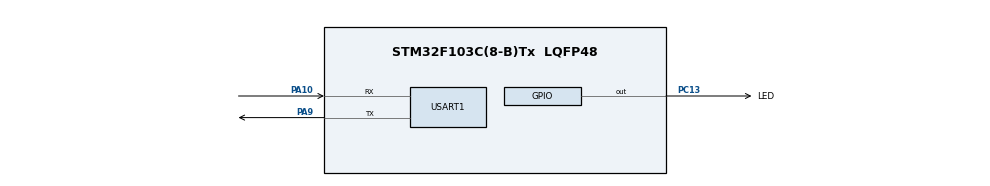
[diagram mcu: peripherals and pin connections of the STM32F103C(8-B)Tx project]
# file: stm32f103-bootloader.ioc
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Mcu.Family=STM32F1
Mcu.Name=STM32F103C(8-B)Tx
Mcu.Package=LQFP48
NVIC.PriorityGroup=NVIC_PRIORITYGROUP_4
NVIC.TIM4_IRQn=true\:0\:0\:false\:false\:true\:true\:true\:true
NVIC.USART1_IRQn=true\:0\:0\:false\:false\:true\:true\:true\:true
PA10.Mode=Asynchronous
PA10.Signal=USART1_RX
PA13.Mode=Serial_Wire
PA13.Signal=SYS_JTMS-SWDIO
PA14.Mode=Serial_Wire
PA14.Signal=SYS_JTCK-SWCLK
PA9.Mode=Asynchronous
PA9.Signal=USART1_TX
PC13-TAMPER-RTC.GPIO_Label=LED
PC13-TAMPER-RTC.Signal=GPIO_Output
PD0-OSC_IN.Mode=HSE-External-Oscillator
PD0-OSC_IN.Signal=RCC_OSC_IN
PD1-OSC_OUT.Mode=HSE-External-Oscillator
PD1-OSC_OUT.Signal=RCC_OSC_OUT
ProjectManager.HeapSize=0x200
ProjectManager.StackSize=0x400
ProjectManager.TargetToolchain=STM32CubeIDE
RCC.AHBFreq_Value=72000000
RCC.APB1CLKDivider=RCC_HCLK_DIV2
RCC.APB1Freq_Value=36000000
RCC.APB1TimFreq_Value=72000000
RCC.APB2Freq_Value=72000000
RCC.APB2TimFreq_Value=72000000
RCC.HCLKFreq_Value=72000000
RCC.PLLMUL=RCC_PLL_MUL9
RCC.PLLSourceVirtual=RCC_PLLSOURCE_HSE
RCC.SYSCLKFreq_VALUE=72000000
RCC.SYSCLKSource=RCC_SYSCLKSOURCE_PLLCLK
RCC.USBFreq_Value=72000000
TIM4.Period=71
TIM4.Prescaler=1749
TIM4.TIM_MasterOutputTrigger=TIM_TRGO_UPDATE
USART1.VirtualMode=VM_ASYNC
VP_TIM4_VS_ClockSourceINT.Mode=Internal
board=custom

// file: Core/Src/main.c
/* USER CODE BEGIN Header */
/**
 ******************************************************************************
 * @file           : main.c
 * @brief          : Main program body
 ******************************************************************************
 * @attention
 *
 * Copyright (c) 2023 STMicroelectronics.
 * All rights reserved.
 *
 * This software is licensed under terms that can be found in the LICENSE file
 * in the root directory of this software component.
 * If no LICENSE file comes with this software, it is provided AS-IS.
 *
 ******************************************************************************
 */
/* USER CODE END Header */
#include "main.h"

/* USER CODE BEGIN Includes */
#include "modbus_callbacks.h"
#include "bootloader.h"

#include <stddef.h>

#include "mb.h"
/* USER CODE END Includes */

/* USER CODE BEGIN PV */
int bootloader_started_programming;
int bootloader_needs_reset;
/* USER CODE END PV */

void SystemClock_Config(void);
static void MX_GPIO_Init(void);
static void MX_USART1_UART_Init(void);
static void MX_TIM4_Init(void);

int main(void)
{

  /* MCU Configuration--------------------------------------------------------*/

  /* Reset of all peripherals, Initializes the Flash interface and the Systick. */
  LL_APB2_GRP1_EnableClock(LL_APB2_GRP1_PERIPH_AFIO);
  LL_APB1_GRP1_EnableClock(LL_APB1_GRP1_PERIPH_PWR);

  /* System interrupt init*/
  NVIC_SetPriorityGrouping(NVIC_PRIORITYGROUP_4);

  /* SysTick_IRQn interrupt configuration */
  NVIC_SetPriority(SysTick_IRQn,
      NVIC_EncodePriority(NVIC_GetPriorityGrouping(), 15, 0));

  /** NOJTAG: JTAG-DP Disabled and SW-DP Enabled
   */
  LL_GPIO_AF_Remap_SWJ_NOJTAG();

  /* Configure the system clock */
  SystemClock_Config();

  /* Initialize all configured peripherals */
  MX_GPIO_Init();
  MX_USART1_UART_Init();
  MX_TIM4_Init();
  /* USER CODE BEGIN 2 */
  eMBInit(MB_RTU, 1, 0, 115200, MB_PAR_NONE);
  eMBEnable();
  eMBRegisterCB(MB_FLASH_UPDATE_FUNCION_CODE, eMBFlashUpdateCB);
  /* USER CODE END 2 */

  /* Infinite loop */
  /* USER CODE BEGIN WHILE */

  for (int i = 0; i < 50; ++i) {
    eMBPoll();
    if (bootloader_started_programming) {
      bootloader_started_programming = 0;
      LL_GPIO_SetOutputPin(LED_GPIO_Port, LED_Pin);
      while (1) {
        eMBPoll();
        if (bootloader_needs_reset) {
          LL_mDelay(100);
          bootloader_needs_reset = 0;
          bootloader_reset_device();
        }
      }
    }

    LL_mDelay(100);
    LL_GPIO_TogglePin(LED_GPIO_Port, LED_Pin);
    /* USER CODE END WHILE */

    /* USER CODE BEGIN 3 */
  }

  LL_GPIO_ResetOutputPin(LED_GPIO_Port, LED_Pin);

  eMBRegisterCB(MB_FLASH_UPDATE_FUNCION_CODE, NULL);
  eMBDisable();
  eMBClose();
  LL_TIM_DeInit(TIM4);
  LL_USART_DeInit(USART1);
  LL_GPIO_DeInit(GPIOC);

  bootloader_app_run();

  /* USER CODE END 3 */
}

void SystemClock_Config(void)
{
  LL_FLASH_SetLatency(LL_FLASH_LATENCY_2);
  while (LL_FLASH_GetLatency() != LL_FLASH_LATENCY_2) {
  }
  LL_RCC_HSE_Enable();

  /* Wait till HSE is ready */
  while (LL_RCC_HSE_IsReady() != 1) {

  }
  LL_RCC_PLL_ConfigDomain_SYS(LL_RCC_PLLSOURCE_HSE_DIV_1, LL_RCC_PLL_MUL_9);
  LL_RCC_PLL_Enable();

  /* Wait till PLL is ready */
  while (LL_RCC_PLL_IsReady() != 1) {

  }
  LL_RCC_SetAHBPrescaler(LL_RCC_SYSCLK_DIV_1);
  LL_RCC_SetAPB1Prescaler(LL_RCC_APB1_DIV_2);
  LL_RCC_SetAPB2Prescaler(LL_RCC_APB2_DIV_1);
  LL_RCC_SetSysClkSource(LL_RCC_SYS_CLKSOURCE_PLL);

  /* Wait till System clock is ready */
  while (LL_RCC_GetSysClkSource() != LL_RCC_SYS_CLKSOURCE_STATUS_PLL) {

  }
  LL_Init1msTick(72000000);
  LL_SetSystemCoreClock(72000000);
}

static void MX_TIM4_Init(void)
{

  LL_TIM_InitTypeDef TIM_InitStruct = { 0 };

  /* Peripheral clock enable */
  LL_APB1_GRP1_EnableClock(LL_APB1_GRP1_PERIPH_TIM4);

  /* TIM4 interrupt Init */
  NVIC_SetPriority(TIM4_IRQn,
      NVIC_EncodePriority(NVIC_GetPriorityGrouping(), 0, 0));
  NVIC_EnableIRQ(TIM4_IRQn);

  TIM_InitStruct.Prescaler = 1749;
  TIM_InitStruct.CounterMode = LL_TIM_COUNTERMODE_UP;
  TIM_InitStruct.Autoreload = 71;
  TIM_InitStruct.ClockDivision = LL_TIM_CLOCKDIVISION_DIV1;
  LL_TIM_Init(TIM4, &TIM_InitStruct);
  LL_TIM_DisableARRPreload(TIM4);
  LL_TIM_SetClockSource(TIM4, LL_TIM_CLOCKSOURCE_INTERNAL);
  LL_TIM_SetTriggerOutput(TIM4, LL_TIM_TRGO_UPDATE);
  LL_TIM_DisableMasterSlaveMode(TIM4);

}

static void MX_USART1_UART_Init(void)
{

  LL_USART_InitTypeDef USART_InitStruct = { 0 };

  LL_GPIO_InitTypeDef GPIO_InitStruct = { 0 };

  /* Peripheral clock enable */
  LL_APB2_GRP1_EnableClock(LL_APB2_GRP1_PERIPH_USART1);

  LL_APB2_GRP1_EnableClock(LL_APB2_GRP1_PERIPH_GPIOA);
  /**USART1 GPIO Configuration
   PA9   ------> USART1_TX
   PA10   ------> USART1_RX
   */
  GPIO_InitStruct.Pin = LL_GPIO_PIN_9;
  GPIO_InitStruct.Mode = LL_GPIO_MODE_ALTERNATE;
  GPIO_InitStruct.Speed = LL_GPIO_SPEED_FREQ_HIGH;
  GPIO_InitStruct.OutputType = LL_GPIO_OUTPUT_PUSHPULL;
  LL_GPIO_Init(GPIOA, &GPIO_InitStruct);

  GPIO_InitStruct.Pin = LL_GPIO_PIN_10;
  GPIO_InitStruct.Mode = LL_GPIO_MODE_FLOATING;
  LL_GPIO_Init(GPIOA, &GPIO_InitStruct);

  /* USART1 interrupt Init */
  NVIC_SetPriority(USART1_IRQn,
      NVIC_EncodePriority(NVIC_GetPriorityGrouping(), 0, 0));
  NVIC_EnableIRQ(USART1_IRQn);

  USART_InitStruct.BaudRate = 115200;
  USART_InitStruct.DataWidth = LL_USART_DATAWIDTH_8B;
  USART_InitStruct.StopBits = LL_USART_STOPBITS_1;
  USART_InitStruct.Parity = LL_USART_PARITY_NONE;
  USART_InitStruct.TransferDirection = LL_USART_DIRECTION_TX_RX;
  USART_InitStruct.HardwareFlowControl = LL_USART_HWCONTROL_NONE;
  USART_InitStruct.OverSampling = LL_USART_OVERSAMPLING_16;
  LL_USART_Init(USART1, &USART_InitStruct);
  LL_USART_ConfigAsyncMode(USART1);
  LL_USART_Enable(USART1);

}

static void MX_GPIO_Init(void)
{
  LL_GPIO_InitTypeDef GPIO_InitStruct = { 0 };

  /* GPIO Ports Clock Enable */
  LL_APB2_GRP1_EnableClock(LL_APB2_GRP1_PERIPH_GPIOC);
  LL_APB2_GRP1_EnableClock(LL_APB2_GRP1_PERIPH_GPIOD);
  LL_APB2_GRP1_EnableClock(LL_APB2_GRP1_PERIPH_GPIOA);

  /**/
  LL_GPIO_ResetOutputPin(LED_GPIO_Port, LED_Pin);

  /**/
  GPIO_InitStruct.Pin = LED_Pin;
  GPIO_InitStruct.Mode = LL_GPIO_MODE_OUTPUT;
  GPIO_InitStruct.Speed = LL_GPIO_SPEED_FREQ_LOW;
  GPIO_InitStruct.OutputType = LL_GPIO_OUTPUT_PUSHPULL;
  LL_GPIO_Init(LED_GPIO_Port, &GPIO_InitStruct);

}

void Error_Handler(void)
{
  __disable_irq();
  while (1) {
  }
}
